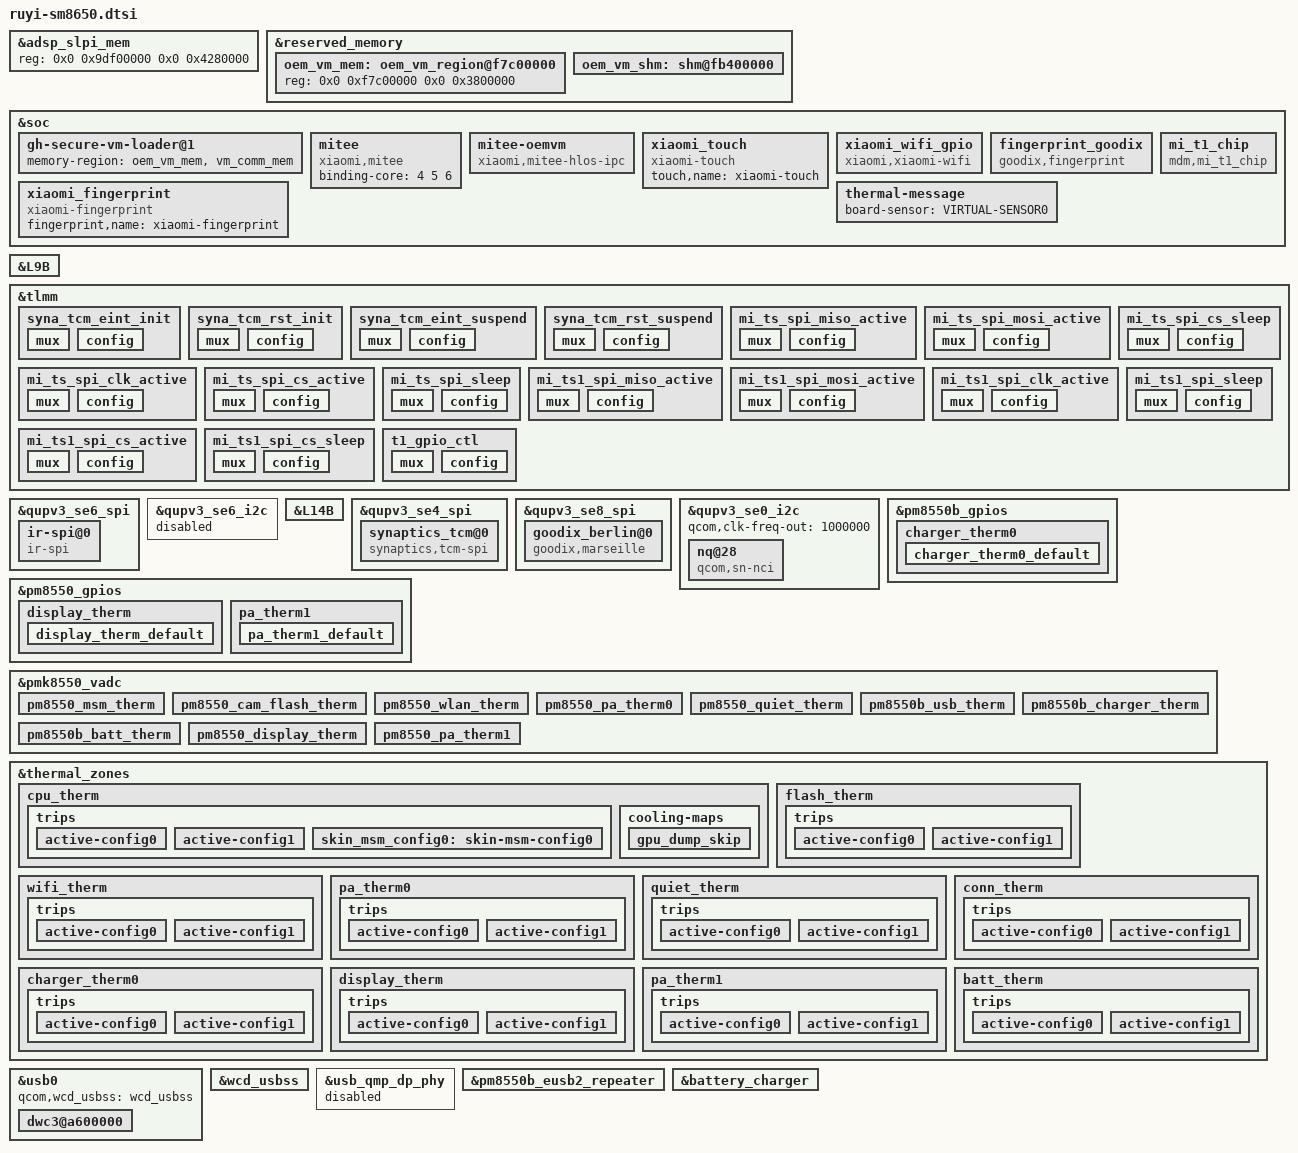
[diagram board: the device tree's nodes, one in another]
/*
  this file is for attribution only of ruyi
  And public attribution of xiaomi platforms(like N2 and so and)
*/
#define SHENNONG_HOUJI_REGULATOR_OCP
#include "ruyi-pinctrl.dtsi"
#include "xiaomi-sm8650-common.dtsi"

&adsp_slpi_mem {
	reg = <0x0 0x9df00000 0x0 0x4280000>;
};

/* mitee vm */
&reserved_memory {
	oem_vm_mem: oem_vm_region@f7c00000 {
		reg = <0x0 0xf7c00000 0x0 0x3800000>;
	};

	oem_vm_shm: shm@fb400000 {
		no-map;
		reg = <0x0 0xfb400000 0x0 0x400000>;
		gunyah-label = <0x3>;
	};
};

&soc {
	gh-secure-vm-loader@1 {
		memory-region = <&oem_vm_mem &vm_comm_mem>;
	};

	mitee: mitee {
		compatible = "xiaomi,mitee";
		binding-core = <4 5 6>;
	};

	mitee-oemvm {
		compatible = "xiaomi,mitee-hlos-ipc";
		xiaomi,master;
		gunyah-shm-label = <0x3>;
		peer-name = <0x4>;
		shared-buffer = <&oem_vm_shm>;
	};
};
/* mitee vm */

&soc {
	xiaomi_touch {
		compatible = "xiaomi-touch";
		status = "ok";
		touch,name = "xiaomi-touch";
	};

	xiaomi_wifi_gpio {
		compatible = "xiaomi,xiaomi-wifi";
		gpio = <&tlmm 163 GPIO_ACTIVE_LOW>;
		debounce-time = <30>;
		pinctrl-names = "default";
		pinctrl-0 = <&wifi_ctrl_irq>;
		status = "ok";
	};

	fingerprint_goodix {
		compatible = "goodix,fingerprint";
		fp_vdd_vreg-supply = <&L9B>;
		goodix,gpio-reset = <&tlmm 89 0x0>;
		goodix,gpio-irq = <&tlmm 90 0x0>;
		status = "ok";
	};

	xiaomi_fingerprint {
		compatible = "xiaomi-fingerprint";
		status = "ok";
		fingerprint,name = "xiaomi-fingerprint";
	};
        
        mi_t1_chip {
                compatible = "mdm,mi_t1_chip";
                gpio-wwan-wlan-1 = <&tlmm 70 0x0>;
                gpio-wwan-wlan-2 = <&tlmm 71 0x0>;
                pinctrl-0       = <&t1_gpio_ctl>;
        };
};

&L9B {
	regulator-min-microvolt = <3300000>;
	regulator-max-microvolt = <3300000>;
	qcom,init-voltage = <3300000>;
};

&tlmm {
	syna_tcm_eint_init: syna_tcm_eint_init {
		mux {
			/* GPIO 162 Interrupt */
			pins = "gpio162";
			function = "gpio";
		};

		config {
			pins = "gpio162";
			bias-disable;
			input-enable;
		};
	};

	syna_tcm_rst_init: syna_tcm_rst_init {
		mux {
			/* GPIO 161 Interrupt */
			pins = "gpio161";
			function = "gpio";
		};

		config {
			pins = "gpio161";
			bias-disable;
			output-low;
		};
	};

	syna_tcm_eint_suspend: syna_tcm_eint_suspend {
		mux {
			/* GPIO 162 Interrupt */
			pins = "gpio162";
			function = "gpio";
		};

		config {
			pins = "gpio162";
			bias-pull-down;
		};
	};

	syna_tcm_rst_suspend: syna_tcm_rst_suspend {
		mux {
			/* GPIO 161 Interrupt */
			pins = "gpio161";
			function = "gpio";
		};

		config {
			pins = "gpio161";
			bias-pull-down;
			output-low;
		};
	};

	mi_ts_spi_miso_active: mi_ts_spi_miso_active {
		mux {
			pins = "gpio48";
			function = "qup1_se4_l0";
		};
		config {
			pins = "gpio48";
			drive-strength = <6>;
			bias-pull-down;
		};
	};

	mi_ts_spi_mosi_active: mi_ts_spi_mosi_active {
		mux {
			pins = "gpio49";
			function = "qup1_se4_l1";
		};
		config {
			pins = "gpio49";
			drive-strength = <6>;
			bias-pull-down;
		};
	};

	mi_ts_spi_clk_active: mi_ts_spi_clk_active {
		mux {
			pins = "gpio50";
			function = "qup1_se4_l2";
		};
		config {
			pins = "gpio50";
			drive-strength = <6>;
			bias-pull-down;
		};
	};

	mi_ts_spi_cs_active: mi_ts_spi_cs_active {
		mux {
			pins = "gpio51";
			function = "qup1_se4_l3";
		};
		config {
			pins = "gpio51";
			drive-strength = <6>;
			bias-pull-down;
		};
	};


	mi_ts_spi_cs_sleep: mi_ts_spi_cs_sleep {
		mux {
			pins = "gpio51";
			function = "gpio";
		};
		config {
			pins = "gpio51";
			drive-strength = <6>;
			bias-pull-down;
		};
	};


	mi_ts_spi_sleep: mi_ts_spi_sleep {
		mux {
			pins = "gpio48", "gpio49",
				"gpio50";
			function = "gpio";
		};
		config {
			pins = "gpio48", "gpio49",
				"gpio50";
			drive-strength = <2>;
			bias-pull-down;
		};
	};

	mi_ts1_spi_miso_active: mi_ts1_spi_miso_active {
		mux {
			pins = "gpio0";
			function = "qup2_se0_l0";
		};
		config {
			pins = "gpio0";
			drive-strength = <6>;
			bias-disable;
		};
	};

	mi_ts1_spi_mosi_active: mi_ts1_spi_mosi_active {
		mux {
			pins = "gpio1";
			function = "qup2_se0_l1";
		};
		config {
			pins = "gpio1";
			drive-strength = <6>;
			bias-disable;
		};
	};

	mi_ts1_spi_clk_active: mi_ts1_spi_clk_active {
		mux {
			pins = "gpio2";
			function = "qup2_se0_l2";
		};
		config {
			pins = "gpio2";
			drive-strength = <6>;
			bias-disable;
		};
	};

	mi_ts1_spi_cs_active: mi_ts1_spi_cs_active {
		mux {
			pins = "gpio3";
			function = "qup2_se0_l3";
		};
		config {
			pins = "gpio3";
			drive-strength = <6>;
			bias-disable;
		};
	};


	mi_ts1_spi_cs_sleep: mi_ts1_spi_cs_sleep {
		mux {
			pins = "gpio3";
			function = "gpio";
		};
		config {
			pins = "gpio3";
			drive-strength = <6>;
			bias-disable;
		};
	};


	mi_ts1_spi_sleep: mi_ts1_spi_sleep {
		mux {
			pins = "gpio0", "gpio1",
				"gpio2";
			function = "gpio";
		};
		config {
			pins = "gpio0", "gpio1",
				"gpio2";
			drive-strength = <2>;
			bias-disable;
		};
	};
	t1_gpio_ctl: t1_gpio_ctl {
		mux {
			pins = "gpio70", "gpio71";
			function = "gpio";
		};
		config {
			pins = "gpio70", "gpio71";
			drive-strength = <2>;
			bias-disable;
			output-enable;
		};
	};
};

&qupv3_se6_spi {
	status = "ok";
	ir-spi@0 {
		compatible = "ir-spi";
		reg = <0>;
		spi-max-frequency = <19200000>;
		status = "ok";
	};
};

&qupv3_se6_i2c {
	status = "disabled";
};

&L14B {
	regulator-min-microvolt = <3300000>;
	regulator-max-microvolt = <3300000>;
	qcom,init-voltage = <3300000>;
};

&qupv3_se4_spi {
	status = "ok";
	qcom,rt;
	pinctrl-0 = <&mi_ts_spi_mosi_active>, <&mi_ts_spi_miso_active>,
				<&mi_ts_spi_clk_active>;
	pinctrl-1 = <&mi_ts_spi_sleep>;
	synaptics_tcm@0 {
		compatible = "synaptics,tcm-spi";
		reg = <0x0>;
		spi-max-frequency = <15000000>;
		interrupt-parent = <&tlmm>;
		interrupts = <162 0x2008>;
		synaptics,avdd-name = "avdd";
		avdd-supply = <&L14B>;
		synaptics,iovdd-name = "iovdd";
		iovdd-supply = <&L12B>;
		/*synaptics,bus-reg-name = "vdd";*/
		/*synaptics,pwr-reg-name = "avdd";*/
		synaptics,irq-gpio = <&tlmm 162 0x2008>;
		synaptics,reset-gpio = <&tlmm 161 0x00>;
		synaptics,irq-on-state = <0>;
		synaptics,spi-mode = <0>;
		synaptics,byte-delay-us = <0>;
		synaptics,block-delay-us = <0>;
		synaptics,power-delay-ms = <50>;
		synaptics,reset-active-ms = <10>;
		synaptics,reset-delay-ms = <200>;
		pinctrl-names = "pmx_ts_active","pmx_ts_suspend";
		pinctrl-0 = <&syna_tcm_eint_init &syna_tcm_rst_init &mi_ts_spi_cs_active>;
		pinctrl-1 = <&syna_tcm_eint_suspend &syna_tcm_rst_suspend &mi_ts_spi_cs_sleep>;
		synaptics,default-test-limit-name = "ruyi_test_limits_S3910P.csv";
		mi_tp,game-mode-array =
				<1 0 0 0 0>;  /* MAX MIN DEF SET GET	*/
		mi_tp,active-mode-array =
				<1 0 0 0 0>;  /* MAX MIN DEF SET GET	*/
		mi_tp,tolerance-array =
				<4 0 2 2 2>;  /* MAX MIN DEF SET GET	*/
		mi_tp,up-threshold-array =
				<4 0 3 3 3>;  /* MAX MIN DEF SET GET	*/
		mi_tp,aim-sensitivity-array =
				<4 0 2 2 2>;  /* MAX MIN DEF SET GET	*/
		mi_tp,tap-stability-array =
				<4 0 2 2 2>;  /* MAX MIN DEF SET GET	*/
		mi_tp,edge-filter-array =
				<3 0 2 2 2>;  /* MAX MIN DEF SET GET	*/
		mi_tp,panel-orien-array =
				<3 0 0 0 0>;  /* MAX MIN DEF SET GET	*/
		mi_tp,report-rate-array =
				<3 0 0 0 0>;  /* MAX MIN DEF SET GET	*/
		mi_tp,expert-mode-array =
				<3 1 1 1 1>;  /* MAX MIN DEF SET GET	*/
		mi_tp,cornerfilter-area-step-array = <0 100 170 250>; /* step 0 to step 3 */
		mi_tp,cornerzone-filter-hor1-array =
                /* B0:Type, B1:pos, B2:x0, B3:y0, B4:x1, B5:y1, B6:reserved, B7: reserved */
                        <0 0 0 0 170 170 0 0>,
                        <0 1 0 0 0 0 0 0>,
                        <0 2 0 2741 170 2911 0 0>,
                        <0 3 0 0 0 0 0 0>;
		mi_tp,cornerzone-filter-hor2-array =
                /* B0:Type, B1:pos, B2:x0, B3:y0, B4:x1, B5:y1, B6:reserved, B7: reserved */
                        <0 0 0 0 0 0 0 0>,
                        <0 1 1053 0 1223 170 0 0>,
                        <0 2 0 0 0 0 0 0>,
                        <0 3 1053 2741 1223 2911 0 0>;
		mi_tp,cornerzone-filter-ver-array =
                /* B0:Type, B1:pos, B2:x0, B3:y0, B4:x1, B5:y1, B6:reserved, B7: reserved */
                        <0 0 0 0 0 0 0 0>,
                        <0 1 0 0 0 0 0 0>,
                        <0 2 0 2611 150 2911 0 0>,
                        <0 3 1073 2611 1223 2911 0 0>;
		mi_tp,deadzone-filter-hor-array =
                /* B0:Type, B1:pos, B2:x0, B3:y0, B4:x1, B5:y1, B6:reserved, B7: reserved */
                        <2 0 0 0 1223 5 0 0>,
                        <2 1 0 2906 1223 2911 0 0>,
                        <2 2 0 0 0 0 0 0>,
                        <2 3 0 0 0 0 0 0>;
		mi_tp,deadzone-filter-ver-array =
                /* B0:Type, B1:pos, B2:x0, B3:y0, B4:x1, B5:y1, B6:reserved, B7: reserved */
                        <2 0 0 0 0 0 0 0>,
                        <2 1 0 0 0 0 0 0>,
                        <2 2 0 0 5 2911 0 0>,
                        <2 3 1218 0 1223 2911 0 0>;
		mi_tp,edgezone-filter-hor-array =
                /* B0:Type, B1:pos, B2:x0, B3:y0, B4:x1, B5:y1, B6:reserved, B7: reserved */
                        <1 0 0 0 1223 40 0 0>,
                        <1 1 0 2871 1223 2911 0 0>,
                        <1 2 0 0 40 2911 0 0>,
                        <1 3 1183 0 1223 2911 0 0>;
		mi_tp,edgezone-filter-ver-array =
                /* B0:Type, B1:pos, B2:x0, B3:y0, B4:x1, B5:y1, B6:reserved, B7: reserved */
                        <1 0 0 0 0 0 0 0>,
                        <1 1 0 0 0 0 0 0>,
                        <1 2 0 0 40 2911 0 0>,
                        <1 3 1183 0 1223 2911 0 0>;
	};
};

&qupv3_se8_spi {
	status = "ok";
	qcom,rt;
	pinctrl-0 = <&mi_ts1_spi_mosi_active>, <&mi_ts1_spi_miso_active>,
				<&mi_ts1_spi_clk_active>;
	pinctrl-1 = <&mi_ts1_spi_sleep>;
	goodix_berlin@0 {
		compatible = "goodix,marseille";
		reg = <0x0>;
		spi-max-frequency = <10000000>;
		//goodix,avdd-gpio = <&tlmm 106 0x00>;
		goodix,avdd-name = "avdd";
		avdd-supply = <&L8B>;
		goodix,iovdd-gpio = <&tlmm 105 0x00>;
		goodix,reset-gpio = <&tlmm 62 0x00>;
		goodix,irq-gpio = <&tlmm 63 0x00>;
		goodix,irq-flags = <2>;
		goodix,panel-max-x = <1208>;
		goodix,panel-max-y = <1392>;
		goodix,panel-max-w = <255>;

		goodix,panel-max-p = <4096>;
		goodix,sleep-enable;
		goodix,firmware-name = "goodix_firmware_ruyi.bin";
		goodix,config-name = "goodix_cfg_group_ruyi.bin";
		pinctrl-names = "pmx_ts1_active", "pmx_ts1_suspend";
		pinctrl-0 = <&mi_ts1_spi_cs_active>;
		pinctrl-1 = <&mi_ts1_spi_cs_sleep>;
		mi_tp,panel-orien-array =
				<3 0 0 0 0>;  /* MAX MIN DEF SET GET	*/
	};
};

&qupv3_se0_i2c {
	status = "ok";
	qcom,clk-freq-out = <1000000>;
	#address-cells = <1>;
	#size-cells = <0>;
	nq@28 {
		compatible = "qcom,sn-nci";
		reg = <0x28>;
		qcom,sn-irq = <&tlmm 75 0x00>;
		qcom,sn-ven = <&tlmm 34 0x00>;
		qcom,sn-clkreq = <&tlmm 35 0x00>;
		qcom,sn-szone = "enable";
		qcom,sn-vdd-1p8-supply = <&L3C>;
		qcom,sn-vdd-1p8-voltage = <1200000 1200000>;
		qcom,sn-vdd-1p8-current = <157000>;
		interrupt-parent = <&tlmm>;
		interrupts = <75 0>;
		interrupt-names = "nfc_irq";
		pinctrl-names = "nfc_active", "nfc_suspend";
		pinctrl-0 = <&nfc_int_active &nfc_enable_active>;
		pinctrl-1 = <&nfc_int_suspend &nfc_enable_suspend>;
	};
};

&pm8550b_gpios {
	charger_therm0 {
		charger_therm0_default: charger_therm0_default {
		pins = "gpio10";
		bias-high-impedance;
		};
	};
};

&pm8550_gpios {
	display_therm {
		display_therm_default: display_therm_default {
		pins = "gpio2";
		bias-high-impedance;
		};
	};
};

&pm8550_gpios {
	pa_therm1 {
		pa_therm1_default: pa_therm1_default {
		pins = "gpio3";
		bias-high-impedance;
		};
	};
};

&pmk8550_vadc {
	pinctrl-names = "default";
	pinctrl-0 = <&display_therm_default>, <&charger_therm0_default>,<&pa_therm1_default>;

	pm8550_msm_therm {
		reg = <PM8550_ADC5_GEN3_AMUX_THM1_100K_PU>;
		label = "pm8550_msm_therm";
		qcom,ratiometric;
		qcom,hw-settle-time = <200>;
		qcom,pre-scaling = <1 1>;
		qcom,adc-tm-type = <1>;
	};

	pm8550_cam_flash_therm {
		reg = <PM8550_ADC5_GEN3_AMUX_THM2_100K_PU>;
		label = "pm8550_cam_flash_therm";
		qcom,ratiometric;
		qcom,hw-settle-time = <200>;
		qcom,pre-scaling = <1 1>;
		qcom,adc-tm-type = <1>;
	};

	pm8550_wlan_therm {
		reg = <PM8550_ADC5_GEN3_AMUX_THM3_100K_PU>;
		label = "pm8550_wlan_therm";
		qcom,ratiometric;
		qcom,hw-settle-time = <200>;
		qcom,pre-scaling = <1 1>;
		qcom,adc-tm-type = <1>;
	};

	pm8550_pa_therm0 {
		reg = <PM8550_ADC5_GEN3_AMUX_THM4_100K_PU>;
		label = "pm8550_pa_therm_0";
		qcom,ratiometric;
		qcom,hw-settle-time = <200>;
		qcom,pre-scaling = <1 1>;
		qcom,adc-tm-type = <1>;
	};

	pm8550_quiet_therm {
		reg = <PM8550_ADC5_GEN3_AMUX_THM5_100K_PU>;
		label = "pm8550_quiet_therm";
		qcom,ratiometric;
		qcom,hw-settle-time = <200>;
		qcom,pre-scaling = <1 1>;
		qcom,adc-tm-type = <1>;
	};

	pm8550b_usb_therm {
		reg = <PM8550B_ADC5_GEN3_AMUX_THM4_USB_THERM_100K_PU>;
		label = "pm8550b_usb_therm";
		qcom,ratiometric;
		qcom,hw-settle-time = <200>;
		qcom,pre-scaling = <1 1>;
		qcom,adc-tm-type = <1>;
	};

	pm8550b_charger_therm {
		reg = <PM8550B_ADC5_GEN3_AMUX_THM6_GPIO10_100K_PU>;
		label = "pm8550b_charger_therm";
		qcom,ratiometric;
		qcom,pre-scaling = <1 1>;
		qcom,adc-tm-type = <1>;
	};
	
	pm8550b_batt_therm {
		reg = <PM8550B_ADC5_GEN3_AMUX_THM1_BATT_THERM_100K_PU>;
		label = "pm8550b_batt_therm";
		qcom,ratiometric;
		qcom,hw-settle-time = <200>;
		qcom,pre-scaling = <1 1>;
		qcom,adc-tm-type = <1>;
	};

	pm8550_display_therm {
 		reg = <PM8550_ADC5_GEN3_AMUX_THM6_GPIO2_100K_PU>;
 		label = "pm8550_display_therm";
 		qcom,ratiometric;
 		qcom,hw-settle-time = <200>;
 		qcom,pre-scaling = <1 1>;
 		qcom,adc-tm-type = <1>;
 	};

	pm8550_pa_therm1 {
 		reg = <PM8550_ADC5_GEN3_AMUX1_GPIO3_100K_PU>;
 		label = "pm8550_pa_therm1";
 		qcom,ratiometric;
 		qcom,hw-settle-time = <200>;
 		qcom,pre-scaling = <1 1>;
 		qcom,adc-tm-type = <1>;
 	};
};

&thermal_zones {
	cpu_therm {
		polling-delay-passive = <0>;
		polling-delay = <0>;
		thermal-sensors = <&pmk8550_vadc PM8550_ADC5_GEN3_AMUX_THM1_100K_PU>;
		trips {
			active-config0 {
				temperature = <125000>;
				hysteresis = <1000>;
				type = "passive";
			};

			active-config1 {
				temperature = <125000>;
				hysteresis = <1000>;
				type = "passive";
			};

			skin_msm_config0: skin-msm-config0 {
				temperature = <60000>;
				hysteresis = <10000>;
				type = "passive";
			};
		};
		cooling-maps {
			gpu_dump_skip {
				trip = <&skin_msm_config0>;
				cooling-device = <&gpu_dump_skip_cdev 1 1>;
			};
		};
	};

	flash_therm {
		polling-delay-passive = <0>;
		polling-delay = <0>;
		thermal-sensors = <&pmk8550_vadc PM8550_ADC5_GEN3_AMUX_THM2_100K_PU>;
		trips {
			active-config0 {
				temperature = <125000>;
				hysteresis = <1000>;
				type = "passive";
			};

			active-config1 {
				temperature = <125000>;
				hysteresis = <1000>;
				type = "passive";
			};
		};
	};

	wifi_therm {
		polling-delay-passive = <0>;
		polling-delay = <0>;
		thermal-sensors = <&pmk8550_vadc PM8550_ADC5_GEN3_AMUX_THM3_100K_PU>;
		trips {
			active-config0 {
				temperature = <125000>;
				hysteresis = <1000>;
				type = "passive";
			};

			active-config1 {
				temperature = <125000>;
				hysteresis = <1000>;
				type = "passive";
			};
		};
	};
	
	pa_therm0 {
		polling-delay-passive = <0>;
		polling-delay = <0>;
		thermal-sensors = <&pmk8550_vadc PM8550_ADC5_GEN3_AMUX_THM4_100K_PU>;
		trips {
			active-config0 {
				temperature = <125000>;
				hysteresis = <1000>;
				type = "passive";
			};

			active-config1 {
				temperature = <125000>;
				hysteresis = <1000>;
				type = "passive";
			};
		};
	};

	quiet_therm {
		polling-delay-passive = <0>;
		polling-delay = <0>;
		thermal-sensors = <&pmk8550_vadc PM8550_ADC5_GEN3_AMUX_THM5_100K_PU>;
		trips {
			active-config0 {
				temperature = <125000>;
				hysteresis = <1000>;
				type = "passive"; 
			};

			active-config1 {
				temperature = <125000>;
				hysteresis = <1000>;
				type = "passive";
			};
		};
	};

	conn_therm {
		polling-delay-passive = <0>;
		polling-delay = <0>;
		thermal-sensors = <&pmk8550_vadc PM8550B_ADC5_GEN3_AMUX_THM4_USB_THERM_100K_PU>;
		trips {
			active-config0 {
				temperature = <125000>;
				hysteresis = <1000>;
				type = "passive";
			};

			active-config1 {
				temperature = <125000>;
				hysteresis = <1000>;
				type = "passive";
			};
		};
	};

	charger_therm0 {
		polling-delay-passive = <0>;
		polling-delay = <0>;
		thermal-sensors = <&pmk8550_vadc PM8550B_ADC5_GEN3_AMUX_THM6_GPIO10_100K_PU>;
		trips {
			active-config0 {
				temperature = <125000>;
				hysteresis = <1000>;
				type = "passive";
			};

			active-config1 {
				temperature = <125000>;
				hysteresis = <1000>;
				type = "passive";
			};
		};
	};

	display_therm {
		polling-delay-passive = <0>;
		polling-delay = <0>;
		thermal-sensors = <&pmk8550_vadc PM8550_ADC5_GEN3_AMUX_THM6_GPIO2_100K_PU>;
		trips {
			active-config0 {
				temperature = <125000>;
				hysteresis = <1000>;
				type = "passive";
			};
			active-config1 {
				temperature = <125000>;
				hysteresis = <1000>;
				type = "passive";
			};
		};
	};

	pa_therm1 {
		polling-delay-passive = <0>;
		polling-delay = <0>;
		thermal-sensors = <&pmk8550_vadc PM8550_ADC5_GEN3_AMUX1_GPIO3_100K_PU>;
		trips {
			active-config0 {
				temperature = <125000>;
				hysteresis = <1000>;
				type = "passive";
			};
			active-config1 {
				temperature = <125000>;
				hysteresis = <1000>;
				type = "passive";
			};
		};
	};
	
	batt_therm {
		polling-delay-passive = <0>;
		polling-delay = <0>;
		thermal-sensors = <&pmk8550_vadc PM8550B_ADC5_GEN3_AMUX_THM1_BATT_THERM_100K_PU>;
		trips {
			active-config0 {
				temperature = <125000>;
				hysteresis = <1000>;
				type = "passive";
			};

			active-config1 {
				temperature = <125000>;
				hysteresis = <1000>;
				type = "passive";
			};
		};
	};
};

&soc {
	thermal-message {
 		board-sensor = "VIRTUAL-SENSOR0";
	};
};
&usb0 {
	qcom,wcd_usbss = <&wcd_usbss>;
	dwc3@a600000 {
		usb-phy = <&eusb2_phy0>, <&usb_nop_phy>;
		maximum-speed = "high-speed";
	};
};
&wcd_usbss {
	wcd-equ-bw-settings = <0xF>;
	wcd-equ-bw-settings-host = <0x8>;
};
&usb_qmp_dp_phy {
	status = "disabled";
	qcom,qmp-phy-init-seq =
		/* <reg_offset, value> */
		<USB3_DP_QSERDES_COM_SSC_STEP_SIZE1_MODE1 0xC0
			USB3_DP_QSERDES_COM_SSC_STEP_SIZE2_MODE1 0x01
			USB3_DP_QSERDES_COM_CP_CTRL_MODE1 0x02
			USB3_DP_QSERDES_COM_PLL_RCTRL_MODE1 0x16
			USB3_DP_QSERDES_COM_PLL_CCTRL_MODE1 0x36
			USB3_DP_QSERDES_COM_CORECLK_DIV_MODE1 0x04
			USB3_DP_QSERDES_COM_LOCK_CMP1_MODE1 0x16
			USB3_DP_QSERDES_COM_LOCK_CMP2_MODE1 0x41
			USB3_DP_QSERDES_COM_DEC_START_MODE1 0x41
			USB3_DP_QSERDES_COM_DEC_START_MSB_MODE1 0x00
			USB3_DP_QSERDES_COM_DIV_FRAC_START1_MODE1 0x55
			USB3_DP_QSERDES_COM_DIV_FRAC_START2_MODE1 0x75
			USB3_DP_QSERDES_COM_DIV_FRAC_START3_MODE1 0x01
			USB3_DP_QSERDES_COM_HSCLK_SEL_1 0x01
			USB3_DP_QSERDES_COM_VCO_TUNE1_MODE1 0x25
			USB3_DP_QSERDES_COM_VCO_TUNE2_MODE1 0x02
			USB3_DP_QSERDES_COM_BIN_VCOCAL_CMP_CODE1_MODE1 0x5C
			USB3_DP_QSERDES_COM_BIN_VCOCAL_CMP_CODE2_MODE1 0x0F
			USB3_DP_QSERDES_COM_BIN_VCOCAL_CMP_CODE1_MODE0 0x5C
			USB3_DP_QSERDES_COM_BIN_VCOCAL_CMP_CODE2_MODE0 0x0F
			USB3_DP_QSERDES_COM_SSC_STEP_SIZE1_MODE0 0xC0
			USB3_DP_QSERDES_COM_SSC_STEP_SIZE2_MODE0 0x01
			USB3_DP_QSERDES_COM_CP_CTRL_MODE0 0x02
			USB3_DP_QSERDES_COM_PLL_RCTRL_MODE0 0x16
			USB3_DP_QSERDES_COM_PLL_CCTRL_MODE0 0x36
			USB3_DP_QSERDES_COM_LOCK_CMP1_MODE0 0x08
			USB3_DP_QSERDES_COM_LOCK_CMP2_MODE0 0x1A
			USB3_DP_QSERDES_COM_DEC_START_MODE0 0x41
			USB3_DP_QSERDES_COM_DEC_START_MSB_MODE0 0x00
			USB3_DP_QSERDES_COM_DIV_FRAC_START1_MODE0 0x55
			USB3_DP_QSERDES_COM_DIV_FRAC_START2_MODE0 0x75
			USB3_DP_QSERDES_COM_DIV_FRAC_START3_MODE0 0x01
			USB3_DP_QSERDES_COM_VCO_TUNE1_MODE0 0x25
			USB3_DP_QSERDES_COM_VCO_TUNE2_MODE0 0x02
			USB3_DP_QSERDES_COM_BG_TIMER 0x0A
			USB3_DP_QSERDES_COM_SSC_EN_CENTER 0x01
			USB3_DP_QSERDES_COM_SSC_PER1 0x62
			USB3_DP_QSERDES_COM_SSC_PER2 0x02
			USB3_DP_QSERDES_COM_SYSCLK_BUF_ENABLE 0x0C
			USB3_DP_QSERDES_COM_SYSCLK_EN_SEL 0x1A
			USB3_DP_QSERDES_COM_LOCK_CMP_CFG 0x14
			USB3_DP_QSERDES_COM_VCO_TUNE_MAP 0x04
			USB3_DP_QSERDES_COM_CORE_CLK_EN 0x20
			USB3_DP_QSERDES_COM_CMN_CONFIG_1 0x16
			USB3_DP_QSERDES_COM_AUTO_GAIN_ADJ_CTRL_1 0xB6
			USB3_DP_QSERDES_COM_AUTO_GAIN_ADJ_CTRL_2 0x4B
			USB3_DP_QSERDES_COM_AUTO_GAIN_ADJ_CTRL_3 0x37
			USB3_DP_QSERDES_COM_ADDITIONAL_MISC 0x0C
			USB3_DP_QSERDES_TXA_RES_CODE_LANE_TX 0x00
			USB3_DP_QSERDES_TXA_RES_CODE_LANE_RX 0x00
			USB3_DP_QSERDES_TXA_RES_CODE_LANE_OFFSET_TX 0x1F
			USB3_DP_QSERDES_TXA_RES_CODE_LANE_OFFSET_RX 0x09
			USB3_DP_QSERDES_TXA_LANE_MODE_1 0xF5
			USB3_DP_QSERDES_TXA_LANE_MODE_3 0x3F
			USB3_DP_QSERDES_TXA_LANE_MODE_4 0x3F
			USB3_DP_QSERDES_TXA_LANE_MODE_5 0x5F
			USB3_DP_QSERDES_TXA_RCV_DETECT_LVL_2 0x12
			USB3_DP_QSERDES_TXA_PI_QEC_CTRL 0x21
			USB3_DP_QSERDES_RXA_UCDR_FO_GAIN 0x0A
			USB3_DP_QSERDES_RXA_UCDR_SO_GAIN 0x06
			USB3_DP_QSERDES_RXA_UCDR_FASTLOCK_FO_GAIN 0x2F
			USB3_DP_QSERDES_RXA_UCDR_SO_SATURATION_AND_ENABLE 0x7F
			USB3_DP_QSERDES_RXA_UCDR_FASTLOCK_COUNT_LOW 0xFF
			USB3_DP_QSERDES_RXA_UCDR_FASTLOCK_COUNT_HIGH 0x0F
			USB3_DP_QSERDES_RXA_UCDR_PI_CONTROLS 0x99
			USB3_DP_QSERDES_RXA_UCDR_SB2_THRESH1 0x08
			USB3_DP_QSERDES_RXA_UCDR_SB2_THRESH2 0x08
			USB3_DP_QSERDES_RXA_UCDR_SB2_GAIN1 0x00
			USB3_DP_QSERDES_RXA_UCDR_SB2_GAIN2 0x0A
			USB3_DP_QSERDES_RXA_AUX_DATA_TCOARSE_TFINE 0xA0
			USB3_DP_QSERDES_RXA_VGA_CAL_CNTRL1 0x54
			USB3_DP_QSERDES_RXA_VGA_CAL_CNTRL2 0x0F
			USB3_DP_QSERDES_RXA_GM_CAL 0x13
			USB3_DP_QSERDES_RXA_RX_EQU_ADAPTOR_CNTRL2 0x0F
			USB3_DP_QSERDES_RXA_RX_EQU_ADAPTOR_CNTRL3 0x4A
			USB3_DP_QSERDES_RXA_RX_EQU_ADAPTOR_CNTRL4 0x0A
			USB3_DP_QSERDES_RXA_RX_IDAC_TSETTLE_LOW 0x07
			USB3_DP_QSERDES_RXA_RX_IDAC_TSETTLE_HIGH 0x00
			USB3_DP_QSERDES_RXA_RX_EQ_OFFSET_ADAPTOR_CNTRL1 0x47
			USB3_DP_QSERDES_RXA_SIGDET_CNTRL 0x04
			USB3_DP_QSERDES_RXA_SIGDET_DEGLITCH_CNTRL 0x0E
			USB3_DP_QSERDES_RXA_RX_MODE_00_LOW 0x3F
			USB3_DP_QSERDES_RXA_RX_MODE_00_HIGH 0xBF
			USB3_DP_QSERDES_RXA_RX_MODE_00_HIGH2 0xFF
			USB3_DP_QSERDES_RXA_RX_MODE_00_HIGH3 0xDF
			USB3_DP_QSERDES_RXA_RX_MODE_00_HIGH4 0xED
			USB3_DP_QSERDES_RXA_RX_MODE_01_LOW 0xDC
			USB3_DP_QSERDES_RXA_RX_MODE_01_HIGH 0x5C
			USB3_DP_QSERDES_RXA_RX_MODE_01_HIGH2 0x9C
			USB3_DP_QSERDES_RXA_RX_MODE_01_HIGH3 0x1D
			USB3_DP_QSERDES_RXA_RX_MODE_01_HIGH4 0x09
			USB3_DP_QSERDES_RXA_DFE_EN_TIMER 0x04
			USB3_DP_QSERDES_RXA_DFE_CTLE_POST_CAL_OFFSET 0x38
			USB3_DP_QSERDES_RXA_DCC_CTRL1 0x0C
			USB3_DP_QSERDES_RXA_VTH_CODE 0x10
			USB3_DP_QSERDES_RXA_SIGDET_CAL_CTRL1 0x14
			USB3_DP_QSERDES_RXA_SIGDET_CAL_TRIM 0x08
			USB3_DP_QSERDES_TXB_RES_CODE_LANE_TX 0x00
			USB3_DP_QSERDES_TXB_RES_CODE_LANE_RX 0x00
			USB3_DP_QSERDES_TXB_RES_CODE_LANE_OFFSET_TX 0x1F
			USB3_DP_QSERDES_TXB_RES_CODE_LANE_OFFSET_RX 0x09
			USB3_DP_QSERDES_TXB_LANE_MODE_1 0xF5
			USB3_DP_QSERDES_TXB_LANE_MODE_3 0x3F
			USB3_DP_QSERDES_TXB_LANE_MODE_4 0x3F
			USB3_DP_QSERDES_TXB_LANE_MODE_5 0x5F
			USB3_DP_QSERDES_TXB_RCV_DETECT_LVL_2 0x12
			USB3_DP_QSERDES_TXB_PI_QEC_CTRL 0x05
			USB3_DP_QSERDES_RXB_UCDR_FO_GAIN 0x0A
			USB3_DP_QSERDES_RXB_UCDR_SO_GAIN 0x06
			USB3_DP_QSERDES_RXB_UCDR_FASTLOCK_FO_GAIN 0x2F
			USB3_DP_QSERDES_RXB_UCDR_SO_SATURATION_AND_ENABLE 0x7F
			USB3_DP_QSERDES_RXB_UCDR_FASTLOCK_COUNT_LOW 0xFF
			USB3_DP_QSERDES_RXB_UCDR_FASTLOCK_COUNT_HIGH 0x0F
			USB3_DP_QSERDES_RXB_UCDR_PI_CONTROLS 0x99
			USB3_DP_QSERDES_RXB_UCDR_SB2_THRESH1 0x08
			USB3_DP_QSERDES_RXB_UCDR_SB2_THRESH2 0x08
			USB3_DP_QSERDES_RXB_UCDR_SB2_GAIN1 0x00
			USB3_DP_QSERDES_RXB_UCDR_SB2_GAIN2 0x0A
			USB3_DP_QSERDES_RXB_AUX_DATA_TCOARSE_TFINE 0xA0
			USB3_DP_QSERDES_RXB_VGA_CAL_CNTRL1 0x54
			USB3_DP_QSERDES_RXB_VGA_CAL_CNTRL2 0x0F
			USB3_DP_QSERDES_RXB_GM_CAL 0x13
			USB3_DP_QSERDES_RXB_RX_EQU_ADAPTOR_CNTRL2 0x0F
			USB3_DP_QSERDES_RXB_RX_EQU_ADAPTOR_CNTRL3 0x4A
			USB3_DP_QSERDES_RXB_RX_EQU_ADAPTOR_CNTRL4 0x0A
			USB3_DP_QSERDES_RXB_RX_IDAC_TSETTLE_LOW 0x07
			USB3_DP_QSERDES_RXB_RX_IDAC_TSETTLE_HIGH 0x00
			USB3_DP_QSERDES_RXB_RX_EQ_OFFSET_ADAPTOR_CNTRL1 0x47
			USB3_DP_QSERDES_RXB_SIGDET_CNTRL 0x04
			USB3_DP_QSERDES_RXB_SIGDET_DEGLITCH_CNTRL 0x0E
			USB3_DP_QSERDES_RXB_RX_MODE_00_LOW 0xBF
			USB3_DP_QSERDES_RXB_RX_MODE_00_HIGH 0xBF
			USB3_DP_QSERDES_RXB_RX_MODE_00_HIGH2 0xBF
			USB3_DP_QSERDES_RXB_RX_MODE_00_HIGH3 0xDF
			USB3_DP_QSERDES_RXB_RX_MODE_00_HIGH4 0xFD
			USB3_DP_QSERDES_RXB_RX_MODE_01_LOW 0xDC
			USB3_DP_QSERDES_RXB_RX_MODE_01_HIGH 0x5C
			USB3_DP_QSERDES_RXB_RX_MODE_01_HIGH2 0x9C
			USB3_DP_QSERDES_RXB_RX_MODE_01_HIGH3 0x1D
			USB3_DP_QSERDES_RXB_RX_MODE_01_HIGH4 0x09
			USB3_DP_QSERDES_RXB_DFE_EN_TIMER 0x04
			USB3_DP_QSERDES_RXB_DFE_CTLE_POST_CAL_OFFSET 0x38
			USB3_DP_QSERDES_RXB_DCC_CTRL1 0x0C
			USB3_DP_QSERDES_RXB_VTH_CODE 0x10
			USB3_DP_QSERDES_RXB_SIGDET_CAL_CTRL1 0x14
			USB3_DP_QSERDES_RXB_SIGDET_CAL_TRIM 0x08
			USB3_DP_PCS_LOCK_DETECT_CONFIG1 0xC4
			USB3_DP_PCS_LOCK_DETECT_CONFIG2 0x89
			USB3_DP_PCS_LOCK_DETECT_CONFIG3 0x20
			USB3_DP_PCS_LOCK_DETECT_CONFIG6 0x13
			USB3_DP_PCS_REFGEN_REQ_CONFIG1 0x21
			USB3_DP_PCS_G12S1_TXMGN_V0 0x1F
			USB3_DP_PCS_G12S1_TXDEEMPH_M3P5DB 0x17
			USB3_DP_PCS_RX_SIGDET_LVL 0x99
			USB3_DP_PCS_RCVR_DTCT_DLY_P1U2_L 0xE7
			USB3_DP_PCS_RCVR_DTCT_DLY_P1U2_H 0x03
			USB3_DP_PCS_CDR_RESET_TIME 0x0A
			USB3_DP_PCS_ALIGN_DETECT_CONFIG1 0x88
			USB3_DP_PCS_ALIGN_DETECT_CONFIG2 0x13
			USB3_DP_PCS_PCS_TX_RX_CONFIG 0x0C
			USB3_DP_PCS_EQ_CONFIG1 0x4B
			USB3_DP_PCS_EQ_CONFIG5 0x10
			USB3_DP_PCS_USB3_POWER_STATE_CONFIG1 0x68
			USB3_DP_PCS_USB3_LFPS_DET_HIGH_COUNT_VAL 0xF8
			USB3_DP_PCS_USB3_RXEQTRAINING_DFE_TIME_S2 0x07
			USB3_DP_PCS_USB3_RCVR_DTCT_DLY_U3_L 0x40
			USB3_DP_PCS_USB3_RCVR_DTCT_DLY_U3_H 0x00>;
};
&pm8550b_eusb2_repeater {
 qcom,param-override-seq-host =
		<0x00 0x50
		0x0F 0x51
		0x04 0x52
		0x07 0x53
		0x02 0x54
		0x01 0x55
		0x03 0x56
		0x07 0x57
		0x02 0x58
		0x01 0x59
		0x03 0x5a
		0x02 0x5b>;
	qcom,param-override-seq =
		<0x00 0x50
		0x0F 0x51
		0x04 0x52
		0x07 0x53
		0x02 0x54
		0x01 0x55
		0x03 0x56
		0x07 0x57
		0x02 0x58
		0x00 0x59
		0x03 0x5a
		0x02 0x5b>;
	qcom,param-override-seq-host-ms =
		<0x00 0x50
		0x05 0x51
		0x01 0x52
		0x07 0x53
		0x01 0x54
		0x01 0x55
		0x03 0x56
		0x03 0x57
		0x02 0x58
		0x01 0x59
		0x03 0x5a
		0x02 0x5b>;
};

&battery_charger {
	qcom,shutdown-voltage = <3150>;
	mi,support-shutdown-delay;
	mi,support-fast-update-timer;
	mi,support-ut-test;
        mi,cycle_volt = "0,100,4210,4250,4450,4540,100,300,4180,4220,4430,4520,300,800,4180,4220,4420,4510,800,10000,4180,4220,4420,4510,";
        mi,cycle_step_curr = "0,800,12300,10821,9410,5646,800,10000,9840,8657,7528,4516,";
        mi,temp_term_curr = "big-small,20,35,743,268,35,40,956,350,40,47,1204,443,";
        mi,thermal = "12300,9900,8700,7900,6500,5900,5450,4950,4350,2970,2570,2110,1880,1480,490,300";
};
